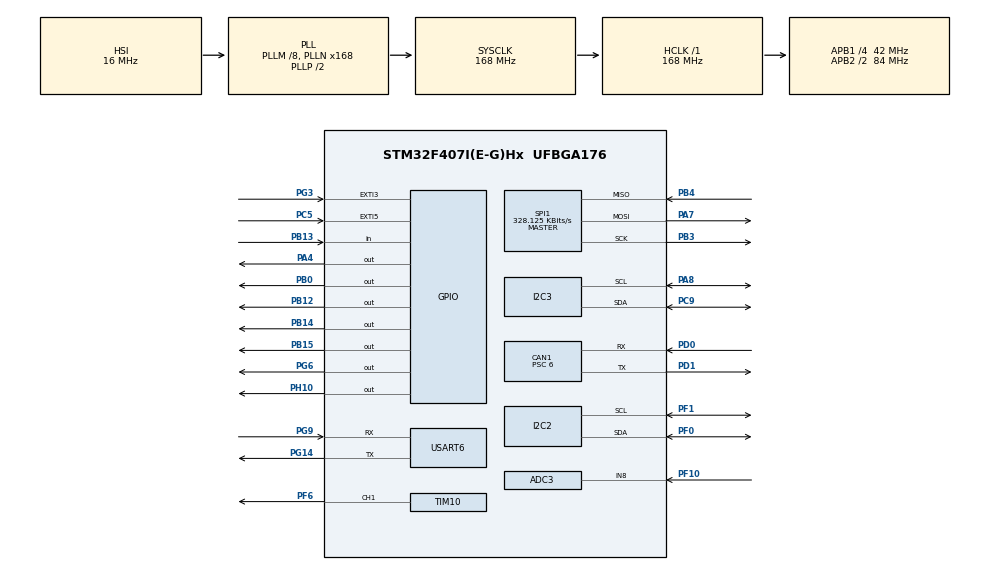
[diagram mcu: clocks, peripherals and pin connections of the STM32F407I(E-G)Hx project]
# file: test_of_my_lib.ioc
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ADC1.Channel-0\#ChannelRegularConversion=ADC_CHANNEL_TEMPSENSOR
ADC1.NbrOfConversionFlag=1
ADC1.Rank-0\#ChannelRegularConversion=1
ADC1.SamplingTime-0\#ChannelRegularConversion=ADC_SAMPLETIME_3CYCLES
ADC1.master=1
ADC3.Channel-1\#ChannelRegularConversion=ADC_CHANNEL_8
ADC3.NbrOfConversionFlag=1
ADC3.Rank-1\#ChannelRegularConversion=1
ADC3.SamplingTime-1\#ChannelRegularConversion=ADC_SAMPLETIME_3CYCLES
CAN1.BS1=CAN_BS1_3TQ
CAN1.BS2=CAN_BS2_3TQ
CAN1.CalculateBaudRate=1000000
CAN1.CalculateTimeBit=1000
CAN1.CalculateTimeQuantum=142.85714285714286
CAN1.Prescaler=6
Dma.Request0=SPI1_TX
Dma.Request1=SPI1_RX
Dma.Request2=USART6_RX
Dma.SPI1_RX.1.Direction=DMA_PERIPH_TO_MEMORY
Dma.SPI1_RX.1.FIFOMode=DMA_FIFOMODE_DISABLE
Dma.SPI1_RX.1.Instance=DMA2_Stream2
Dma.SPI1_RX.1.MemDataAlignment=DMA_MDATAALIGN_BYTE
Dma.SPI1_RX.1.MemInc=DMA_MINC_ENABLE
Dma.SPI1_RX.1.Mode=DMA_NORMAL
Dma.SPI1_RX.1.PeriphDataAlignment=DMA_PDATAALIGN_BYTE
Dma.SPI1_RX.1.PeriphInc=DMA_PINC_DISABLE
Dma.SPI1_RX.1.Priority=DMA_PRIORITY_VERY_HIGH
Dma.SPI1_TX.0.Direction=DMA_MEMORY_TO_PERIPH
Dma.SPI1_TX.0.FIFOMode=DMA_FIFOMODE_DISABLE
Dma.SPI1_TX.0.Instance=DMA2_Stream3
Dma.SPI1_TX.0.MemDataAlignment=DMA_MDATAALIGN_BYTE
Dma.SPI1_TX.0.MemInc=DMA_MINC_ENABLE
Dma.SPI1_TX.0.Mode=DMA_NORMAL
Dma.SPI1_TX.0.PeriphDataAlignment=DMA_PDATAALIGN_BYTE
Dma.SPI1_TX.0.PeriphInc=DMA_PINC_DISABLE
Dma.SPI1_TX.0.Priority=DMA_PRIORITY_HIGH
Dma.USART6_RX.2.Direction=DMA_PERIPH_TO_MEMORY
Dma.USART6_RX.2.FIFOMode=DMA_FIFOMODE_DISABLE
Dma.USART6_RX.2.Instance=DMA2_Stream1
Dma.USART6_RX.2.MemDataAlignment=DMA_MDATAALIGN_BYTE
Dma.USART6_RX.2.MemInc=DMA_MINC_ENABLE
Dma.USART6_RX.2.Mode=DMA_CIRCULAR
Dma.USART6_RX.2.PeriphDataAlignment=DMA_PDATAALIGN_BYTE
Dma.USART6_RX.2.PeriphInc=DMA_PINC_DISABLE
Dma.USART6_RX.2.Priority=DMA_PRIORITY_LOW
I2C3.I2C_Mode=I2C_Fast
Mcu.Family=STM32F4
Mcu.Name=STM32F407I(E-G)Hx
Mcu.Package=UFBGA176
NVIC.CAN1_RX0_IRQn=true\:0\:0\:false\:false\:true\:true\:true\:true
NVIC.CAN1_RX1_IRQn=true\:0\:0\:false\:false\:true\:true\:true\:true
NVIC.DMA2_Stream1_IRQn=true\:0\:0\:false\:false\:true\:false\:true\:true
NVIC.DMA2_Stream2_IRQn=true\:0\:0\:false\:false\:true\:false\:true\:true
NVIC.DMA2_Stream3_IRQn=true\:0\:0\:false\:false\:true\:false\:true\:true
NVIC.EXTI3_IRQn=true\:0\:0\:false\:false\:true\:true\:true\:true
NVIC.PriorityGroup=NVIC_PRIORITYGROUP_4
NVIC.USART6_IRQn=true\:0\:0\:false\:false\:true\:true\:true\:true
PA13.Mode=Serial_Wire
PA13.Signal=SYS_JTMS-SWDIO
PA14.Mode=Serial_Wire
PA14.Signal=SYS_JTCK-SWCLK
PA4.GPIO_PuPd=GPIO_PULLUP
PA4.GPIO_Speed=GPIO_SPEED_FREQ_HIGH
PA4.PinState=GPIO_PIN_SET
PA4.Signal=GPIO_Output
PA7.Mode=Full_Duplex_Master
PA7.Signal=SPI1_MOSI
PA8.Mode=I2C
PA8.Signal=I2C3_SCL
PB0.GPIO_PuPd=GPIO_PULLUP
PB0.GPIO_Speed=GPIO_SPEED_FREQ_HIGH
PB0.PinState=GPIO_PIN_SET
PB0.Signal=GPIO_Output
PB12.GPIO_PuPd=GPIO_PULLDOWN
PB12.GPIO_Speed=GPIO_SPEED_FREQ_HIGH
PB12.Signal=GPIO_Output
PB13.GPIO_PuPd=GPIO_PULLDOWN
PB13.Signal=GPIO_Input
PB14.GPIO_PuPd=GPIO_PULLDOWN
PB14.GPIO_Speed=GPIO_SPEED_FREQ_HIGH
PB14.Signal=GPIO_Output
PB15.GPIO_PuPd=GPIO_PULLDOWN
PB15.GPIO_Speed=GPIO_SPEED_FREQ_HIGH
PB15.Signal=GPIO_Output
PB3.Mode=Full_Duplex_Master
PB3.Signal=SPI1_SCK
PB4.Mode=Full_Duplex_Master
PB4.Signal=SPI1_MISO
PC5.GPIO_ModeDefaultEXTI=GPIO_MODE_IT_FALLING
PC5.GPIO_PuPd=GPIO_PULLUP
PC5.Signal=GPXTI5
PC9.Mode=I2C
PC9.Signal=I2C3_SDA
PD0.Mode=CAN_Activate
PD0.Signal=CAN1_RX
PD1.Mode=CAN_Activate
PD1.Signal=CAN1_TX
PF0.Mode=I2C
PF0.Signal=I2C2_SDA
PF1.Mode=I2C
PF1.Signal=I2C2_SCL
PF10.Mode=IN8
PF10.Signal=ADC3_IN8
PF6.Signal=S_TIM10_CH1
PG14.Mode=Asynchronous
PG14.Signal=USART6_TX
PG3.GPIO_ModeDefaultEXTI=GPIO_MODE_IT_FALLING
PG3.GPIO_PuPd=GPIO_PULLUP
PG3.Signal=GPXTI3
PG6.GPIO_ModeDefaultOutputPP=GPIO_MODE_OUTPUT_PP
PG6.GPIO_PuPd=GPIO_PULLUP
PG6.GPIO_Speed=GPIO_SPEED_FREQ_MEDIUM
PG6.PinState=GPIO_PIN_SET
PG6.Signal=GPIO_Output
PG9.Mode=Asynchronous
PG9.Signal=USART6_RX
PH0-OSC_IN.Mode=HSE-External-Oscillator
PH0-OSC_IN.Signal=RCC_OSC_IN
PH1-OSC_OUT.Mode=HSE-External-Oscillator
PH1-OSC_OUT.Signal=RCC_OSC_OUT
PH10.Signal=GPIO_Output
ProjectManager.HeapSize=0x200
ProjectManager.StackSize=0x400
ProjectManager.TargetToolchain=MDK-ARM V5.32
RCC.48MHZClocksFreq_Value=84000000
RCC.AHBFreq_Value=168000000
RCC.APB1CLKDivider=RCC_HCLK_DIV4
RCC.APB1Freq_Value=42000000
RCC.APB1TimFreq_Value=84000000
RCC.APB2CLKDivider=RCC_HCLK_DIV2
RCC.APB2Freq_Value=84000000
RCC.APB2TimFreq_Value=168000000
RCC.CortexFreq_Value=168000000
RCC.HCLKFreq_Value=168000000
RCC.HSE_VALUE=12000000
RCC.HSI_VALUE=16000000
RCC.LSE_VALUE=32768
RCC.PLLM=8
RCC.PLLN=168
RCC.SYSCLKFreq_VALUE=168000000
RCC.SYSCLKSource=RCC_SYSCLKSOURCE_PLLCLK
RCC.VCOOutputFreq_Value=336000000
SH.S_TIM10_CH1.0=TIM10_CH1,PWM Generation1 CH1
SPI1.BaudRatePrescaler=SPI_BAUDRATEPRESCALER_256
SPI1.CLKPhase=SPI_PHASE_2EDGE
SPI1.CLKPolarity=SPI_POLARITY_HIGH
SPI1.CalculateBaudRate=328.125 KBits/s
SPI1.Direction=SPI_DIRECTION_2LINES
SPI1.Mode=SPI_MODE_MASTER
SPI1.VirtualType=VM_MASTER
TIM10.Channel=TIM_CHANNEL_1
USART6.VirtualMode=VM_ASYNC
VP_ADC1_TempSens_Input.Mode=IN-TempSens
VP_ADC1_Vref_Input.Mode=IN-Vrefint
VP_TIM10_VS_ClockSourceINT.Mode=Enable_Timer
board=custom

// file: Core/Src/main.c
/* USER CODE BEGIN Header */
/**
  ******************************************************************************
  * @file           : main.c
  * @brief          : Main program body
  ******************************************************************************
  * @attention
  *
  * Copyright (c) 2024 STMicroelectronics.
  * All rights reserved.
  *
  * This software is licensed under terms that can be found in the LICENSE file
  * in the root directory of this software component.
  * If no LICENSE file comes with this software, it is provided AS-IS.
  *
  ******************************************************************************
  */
/* USER CODE END Header */
#include "main.h"
#include "adc.h"
#include "can.h"
#include "dma.h"
#include "i2c.h"
#include "spi.h"
#include "tim.h"
#include "usart.h"
#include "gpio.h"

/* USER CODE BEGIN Includes */
#include "PS2.h"
#include "i2c_oled.hpp"
#include "Macanum.h"
#include "ist8310.h"
#include "BMI088.h"
#include "ADCtest.h"
#include "drv_can.h"
#include "maincpp.hpp"
/* USER CODE END Includes */

void SystemClock_Config(void);

int main(void)
{

  /* MCU Configuration--------------------------------------------------------*/

  /* Reset of all peripherals, Initializes the Flash interface and the Systick. */
  HAL_Init();

  /* Configure the system clock */
  SystemClock_Config();

  /* Initialize all configured peripherals */
  MX_GPIO_Init();
  MX_DMA_Init();
  MX_I2C2_Init();
  MX_I2C3_Init();
  MX_CAN1_Init();
  MX_SPI1_Init();
  MX_TIM10_Init();
  MX_ADC1_Init();
  MX_ADC3_Init();
  MX_USART6_UART_Init();
  /* USER CODE BEGIN 2 */
maincpp();
  /* USER CODE END 2 */

  /* Infinite loop */
  /* USER CODE BEGIN WHILE */
  while (1)
  {
    // uint8_t* pdata=PS2_ReadData();
    // OLED_ShowNum_withsign(0,0,pdata[5]-126,6,16,1);
    // OLED_ShowNum_withsign(0,16,pdata[6]-126,6,16,1);
    // OLED_ShowNum_withsign(0,32,pdata[7]-126,6,16,1);
    // OLED_ShowNum_withsign(0,48,pdata[8]-126,6,16,1);
    // OLED_ShowNum_withsign(64,0,ist_data[0],4,16,1);
    // OLED_ShowNum_withsign(64,16,ist_data[1],4,16,1);
    // OLED_ShowNum_withsign(64,32,ist_data[2],4,16,1);
    // OLED_Refresh();

    // BMI088_read(accel,gyro,&temperature);
    // OLED_ShowNum_withsign(0,0,accel[0],6,16,1);
    // OLED_ShowNum_withsign(0,16,accel[1],6,16,1);
    // OLED_ShowNum_withsign(0,32,accel[2],6,16,1);
    // OLED_ShowNum_withsign(64,0,gyro[0],6,16,1);
    // OLED_ShowNum_withsign(64,16,gyro[1],6,16,1);
    // OLED_ShowNum_withsign(64,32,gyro[2],6,16,1);
    // OLED_ShowNum_withsign(0,48,temperature,6,16,1);
    // OLED_ShowNum_withsign(64,48,get_battery_voltage(),6,16,1);
    // OLED_Refresh();

    /* USER CODE END WHILE */

  }
}

void SystemClock_Config(void)
{
  RCC_OscInitTypeDef RCC_OscInitStruct = {0};
  RCC_ClkInitTypeDef RCC_ClkInitStruct = {0};

  /** Configure the main internal regulator output voltage
  */
  __HAL_RCC_PWR_CLK_ENABLE();
  __HAL_PWR_VOLTAGESCALING_CONFIG(PWR_REGULATOR_VOLTAGE_SCALE1);

  /** Initializes the RCC Oscillators according to the specified parameters
  * in the RCC_OscInitTypeDef structure.
  */
  RCC_OscInitStruct.OscillatorType = RCC_OSCILLATORTYPE_HSI;
  RCC_OscInitStruct.HSIState = RCC_HSI_ON;
  RCC_OscInitStruct.HSICalibrationValue = RCC_HSICALIBRATION_DEFAULT;
  RCC_OscInitStruct.PLL.PLLState = RCC_PLL_ON;
  RCC_OscInitStruct.PLL.PLLSource = RCC_PLLSOURCE_HSI;
  RCC_OscInitStruct.PLL.PLLM = 8;
  RCC_OscInitStruct.PLL.PLLN = 168;
  RCC_OscInitStruct.PLL.PLLP = RCC_PLLP_DIV2;
  RCC_OscInitStruct.PLL.PLLQ = 4;
  if (HAL_RCC_OscConfig(&RCC_OscInitStruct) != HAL_OK)
  {
    Error_Handler();
  }

  /** Initializes the CPU, AHB and APB buses clocks
  */
  RCC_ClkInitStruct.ClockType = RCC_CLOCKTYPE_HCLK|RCC_CLOCKTYPE_SYSCLK
                              |RCC_CLOCKTYPE_PCLK1|RCC_CLOCKTYPE_PCLK2;
  RCC_ClkInitStruct.SYSCLKSource = RCC_SYSCLKSOURCE_PLLCLK;
  RCC_ClkInitStruct.AHBCLKDivider = RCC_SYSCLK_DIV1;
  RCC_ClkInitStruct.APB1CLKDivider = RCC_HCLK_DIV4;
  RCC_ClkInitStruct.APB2CLKDivider = RCC_HCLK_DIV2;

  if (HAL_RCC_ClockConfig(&RCC_ClkInitStruct, FLASH_LATENCY_5) != HAL_OK)
  {
    Error_Handler();
  }
}

void Error_Handler(void)
{
  __disable_irq();
  while (1)
  {
  }
}
